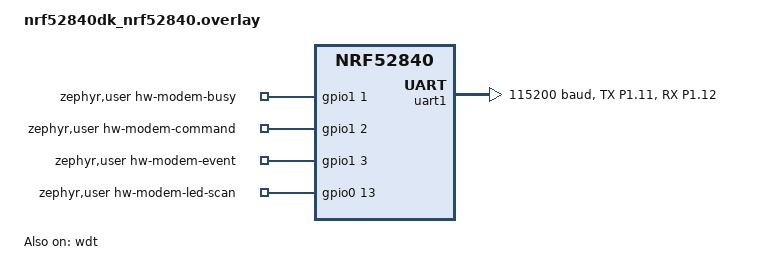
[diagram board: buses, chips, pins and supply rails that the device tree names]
/*
 * Copyright (c) 2024 Semtech Corporation
 *
 * SPDX-License-Identifier: Apache-2.0
 */

/ {
    zephyr,user {
        /* PINS used for the HW modem sample. */
        hw-modem-busy-gpios = <&gpio1 1 GPIO_ACTIVE_HIGH>;
        hw-modem-command-gpios = <&gpio1 2 GPIO_ACTIVE_HIGH>;
        hw-modem-event-gpios = <&gpio1 3 GPIO_ACTIVE_HIGH>;
        hw-modem-led-scan-gpios = <&gpio0 13 GPIO_ACTIVE_HIGH>;
    };

    // soc {
    //     /delete-node/ spi@4002f000;
    //     spi2: arduino_spi: spi@40023000 {};
    // };

    aliases {
        /* Specify which UART is used for communication (as input for the hw modem tester) */
        // smtc-hal-uart = &arduino_serial;
        smtc-hal-uart = &uart1;
        smtc-watchdog = &wdt;
        smtc-lr11xx = &lora_semtech_lr11xxmb1xxs;
    };

    // Change arduino_spi

};

&spi1 {
    status = "disabled";
};
// &spi2 {
//     status = "disabled";
// };

/* Specify which UART is used for communication (as input for the hw modem tester) */
&uart1 {
    status = "okay";

    current-speed = <115200>;

    pinctrl-0 = <&uart1_default_alt>;
    pinctrl-1 = <&uart1_sleep_alt>;
    pinctrl-names = "default", "sleep";
    /delete-property/ hw-flow-control;
};

&pinctrl {
    uart1_default_alt: uart1_default_alt {
        group1 {
            psels = <NRF_PSEL(UART_TX, 1, 11)>,
                    <NRF_PSEL(UART_RX, 1, 12)>;
        };
    };

    uart1_sleep_alt: uart1_sleep_alt {
        group1 {
            psels = <NRF_PSEL(UART_TX, 1, 11)>,
                    <NRF_PSEL(UART_RX, 1, 12)>;
            low-power-enable;
        };
    };
};

&wdt {
    status = "okay";
};

&lora_semtech_lr11xxmb1xxs {
    tcxo-wakeup-time = <7>;
};
